# SCACHE_MMU_DSP register map
Vendor: Texas Instruments
Peripheral module from a debugger description file (folder omap5430_ES2_PUBLIC).
Registers are 32-bit, access per field, reset 0x0 unless marked. A register's access mark holds for its fields unless they carry their own. Offsets are as the file gives them; lines under a group give offsets from that group; [hi:lo] are bit positions; {n}, {i} and the like mark numbered series; 'fields as' and 'values as' point back to an identical list; <NAME> marks a mode.

## SCACHE_MMU_DSP
{0x0+4i} SCACHE_MMU_LARGE_ADDR_i_{i} (i=0..7)
  [31:25] ADDRESS rw — logical source address
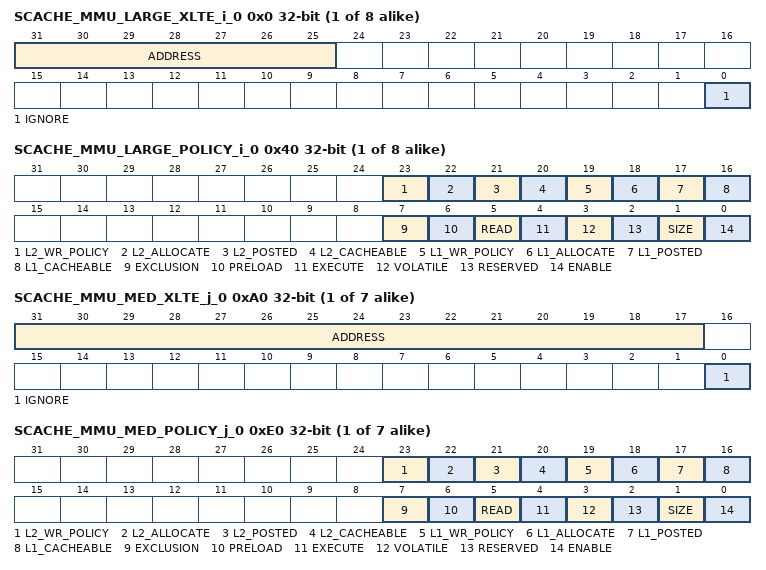
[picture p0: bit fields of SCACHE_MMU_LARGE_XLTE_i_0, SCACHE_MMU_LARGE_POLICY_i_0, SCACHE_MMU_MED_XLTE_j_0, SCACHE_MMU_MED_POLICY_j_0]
{0x0+4i} SCACHE_MMU_LARGE_XLTE_i_{i} (i=0..7) — Large page translated address
  [31:25] ADDRESS rw — Logical source translated address
  [0] IGNORE rw — Do not use translated address.
{0x40+4i} SCACHE_MMU_LARGE_POLICY_i_{i} (i=0..7)
  [23] L2_WR_POLICY rw — L2 write policy
    0=write_through; 1=write_back
  [22] L2_ALLOCATE rw — L2 allocate policy
    0=no_writes_are_allocated; 1=follow_sideband
  [21] L2_POSTED rw — L2 posted policy
    0=not_posted; 1=posted
  [20] L2_CACHEABLE rw — L2 cache policy
    0=non-cacheable; 1=cacheable
  [19] L1_WR_POLICY rw — L1 write policy
    0=write_through; 1=write_back
  [18] L1_ALLOCATE rw — L1 allocate policy
    0=no_writes_are_allocated; 1=follow_sideband
  [17] L1_POSTED rw — L1 posted policy
    0=not_posted; 1=posted
  [16] L1_CACHEABLE rw — L1 cache policy
    0=non-cacheable; 1=cacheable
  [7] EXCLUSION rw — cache exclusion
    0=do_not_send_exclusion_sideband; 1=send_exclusion_sideband
  [6] PRELOAD rw — preload region
    0=do_not_preload; 1=preload
  [5] READ rw — read only
  [4] EXECUTE rw — execute only
  [3] VOLATILE rw — volatile qualifier, see policy matrix
    0=do_not_follow_volatile_qualifier; 1=follow_volatile_qualifier
  [2] RESERVED rw — Read returns 0. Write has no effect.
  [1] SIZE rw — size of page
  [0] ENABLE rw — enable page
    0=page_not_enabled; 1=page_enabled
{0x60+4i} SCACHE_MMU_MED_ADDR_j_{i} (i=0..6)
  [31:17] ADDRESS rw — logical source address
{0xA0+4i} SCACHE_MMU_MED_XLTE_j_{i} (i=0..6) — Medium page translated address
  [31:17] ADDRESS rw — Logical source translated address
  [0] IGNORE rw — Do not use translated address.
{0xE0+4i} SCACHE_MMU_MED_POLICY_j_{i} (i=0..6)
  [23] L2_WR_POLICY rw — L2 write policy
    0=write_through; 1=write_back
  [22] L2_ALLOCATE rw — L2 allocate policy
    0=no_writes_are_allocated; 1=follow_sideband
  [21] L2_POSTED rw — L2 posted policy
    0=non_posted; 1=posted
  [20] L2_CACHEABLE rw — L2 cache policy
    0=non-cacheable; 1=cacheable
  [19] L1_WR_POLICY rw — L1 write policy
    0=write_through; 1=write_back
  [18] L1_ALLOCATE rw — L1 allocate policy
    0=no_writes_are_allocated; 1=follow_sideband
  [17] L1_POSTED rw — L1 posted policy
    0=non_posted; 1=posted
  [16] L1_CACHEABLE rw — L1 cache policy
    0=non-cacheable; 1=cacheable
  [7] EXCLUSION rw — cache exclusion
    0=do_not_send_exclusion_sideband; 1=send_exclusion_sideband
  [6] PRELOAD rw — preload region
    0=do_not_preload; 1=preload
  [5] READ rw — read only
  [4] EXECUTE rw — execute only
  [3] VOLATILE rw — volatile qualifier, see policy matrix
    values as SCACHE_MMU_LARGE_POLICY_i_0.VOLATILE
  [2] RESERVED rw — Read returns 0. Write has no effect.
  [1] SIZE rw — size of page
  [0] ENABLE rw — enable page
    0=page_not_enabled; 1=page_enabled
0x120 SCACHE_MMU_SMALL_ADDR_k_0 (reset mask 0xFFF) — Small Page0 Address
  [31:12] ADDRESS rw — logical source address
0x124 SCACHE_MMU_SMALL_ADDR_k_1 (reset mask 0xFFF) — Small Page0 Address
  [31:12] ADDRESS rw — logical source address
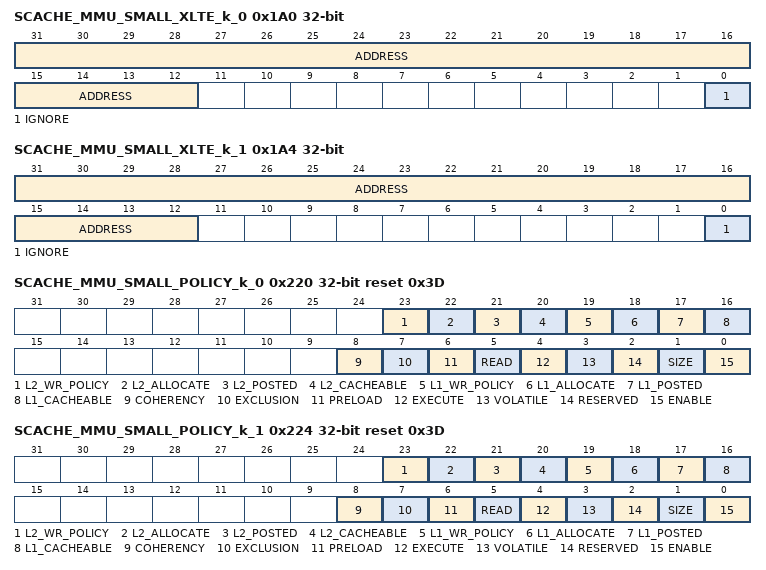
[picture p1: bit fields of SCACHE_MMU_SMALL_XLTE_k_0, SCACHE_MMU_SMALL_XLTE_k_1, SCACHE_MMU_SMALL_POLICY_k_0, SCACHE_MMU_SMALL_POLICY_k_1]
0x1A0 SCACHE_MMU_SMALL_XLTE_k_0 — Small page translated address
  [31:12] ADDRESS rw — Logical source translated address
  [0] IGNORE rw — Do not use translated address.
0x1A4 SCACHE_MMU_SMALL_XLTE_k_1 — Small page translated address
  fields as SCACHE_MMU_SMALL_XLTE_k_0
0x220 SCACHE_MMU_SMALL_POLICY_k_0 reset 0x3D — Small page0 policy
  [23] L2_WR_POLICY rw — L2 write policy
    0=write_through; 1=write_back
  [22] L2_ALLOCATE rw — L2 allocate policy
    0=no_writes_are_allocated; 1=follow_sideband
  [21] L2_POSTED rw — L2 posted policy
    0=non_posted; 1=posted
  [20] L2_CACHEABLE rw — L2 cache policy
    0=non-cacheable; 1=cacheable
  [19] L1_WR_POLICY rw — L1 write policy
    0=write_through; 1=write_back
  [18] L1_ALLOCATE rw — L1 allocate policy
    0=no_writes_are_allocated; 1=follow_sideband
  [17] L1_POSTED rw — L1 posted policy
    0=non_posted; 1=posted
  [16] L1_CACHEABLE rw — L1 cache policy
    0=non-cacheable; 1=cacheable
  [8] COHERENCY ro
  [7] EXCLUSION rw — cache exclusion
    0=do_not_send_exclusion_sideband; 1=send_exclusion_sideband
  [6] PRELOAD rw — preload region
    0=do_not_preload; 1=preload
  [5] READ rw — read only
  [4] EXECUTE rw — execute only
  [3] VOLATILE rw — volatile qualifier, see policy matrix
    values as SCACHE_MMU_LARGE_POLICY_i_0.VOLATILE
  [2] RESERVED rw — Read returns 1. Write has no effect.
  [1] SIZE rw — size of page
  [0] ENABLE rw — enable page
    0=page_not_enabled; 1=page_enabled
0x224 SCACHE_MMU_SMALL_POLICY_k_1 reset 0x3D — Small page0 policy
  fields as SCACHE_MMU_SMALL_POLICY_k_0
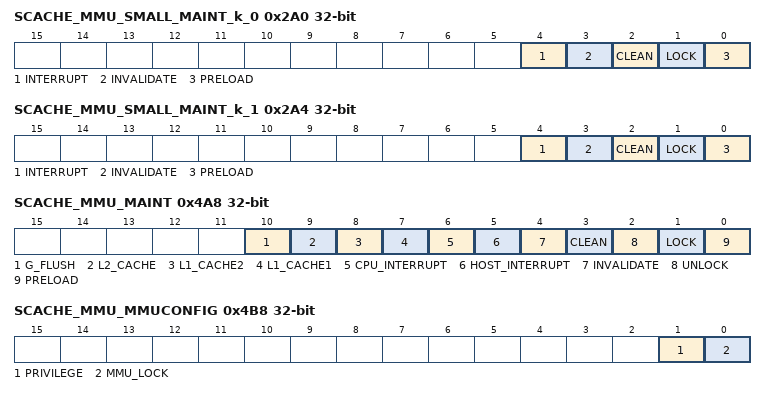
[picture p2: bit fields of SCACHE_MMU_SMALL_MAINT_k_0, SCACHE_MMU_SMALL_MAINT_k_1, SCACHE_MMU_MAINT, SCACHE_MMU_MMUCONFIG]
0x2A0 SCACHE_MMU_SMALL_MAINT_k_0
  [4] INTERRUPT rw — generate interrupt when maintenance operation is complete
  [3] INVALIDATE rw — invalidate page
  [2] CLEAN rw — evict page
  [1] LOCK rw — lock page
  [0] PRELOAD rw — preload page
0x2A4 SCACHE_MMU_SMALL_MAINT_k_1
  fields as SCACHE_MMU_SMALL_MAINT_k_0
0x4A8 SCACHE_MMU_MAINT — Maintenance Configuration Register
  [10] G_FLUSH rw — Global flush bit
    0=do_nothing,_global_flush_done; 1=invalidate_L1+L2
  [9] L2_CACHE rw — do maintenance operation in L2 Cache. Note: Hardware ensures that the maintenance operations are done in L1 first and then in L2
    0=do_nothing; 1=perform maintenance operation selected by the maintenance bits
  [8] L1_CACHE2 rw — do maintenance operation in L1 Cache 2
    values as L2_CACHE
  [7] L1_CACHE1 rw — do maintenance operation in L1 Cache1
    0=do_not_perform_maintenance_operation; 1=perform maintenance operation selected by the maintenance bits
  [6] CPU_INTERRUPT rw — generate interrupt to cpu when maintenance operation initiated by CPU is complete
    0=do_not_generate_interrupt; 1=generate_interrupt
  [5] HOST_INTERRUPT rw — generate interrupt when maintenance operation is complete
    0=do_not_generate_interrupt; 1=generate_interrupt
  [4] INVALIDATE rw — invalidate lines in region defined by maintenance start/end addresses
    0=do_nothing; 1=invalidate
  [3] CLEAN rw — evict dirty lines in region defined by maintenance start/end addresses
    0=do_nothing; 1=clean
  [2] UNLOCK rw — unlock region defined by maintenance start/end addresses
    0=do_nothing; 1=unlock
  [1] LOCK rw — lock region defined by maintenance start/end addresses
    0=do_nothing; 1=lock
  [0] PRELOAD rw — preload region defined by maintenance start/end addresses
    0=do_nothing; 1=preload
0x4AC SCACHE_MMU_MTSTART rw — Maintenance Start Configuratoin Register
  [31:0] BEGIN_ADDRESS — Start address of maintenance operations, resets to 0x0000 when finished
0x4B0 SCACHE_MMU_MTEND rw — Maintenance End Configuration Register
  [31:0] END_ADDRESS — End address of maintenance operations, resets to 0x0000 when finished
0x4B4 SCACHE_MMU_MAINTST ro — Maintenance Status Register
  [0] STATUS — status bit
    0=do_nothing,_maintenance_completed; 1=maintenance_ongoing
0x4B8 SCACHE_MMU_MMUCONFIG — MMU Configuration Register
  [1] PRIVILEGE rw — Privilege bit. Once this bit is set, only global flush, debugger, or hardware reset can clear.
    0=CPU_can_access_everything; 1=CPU_DMA_MMU_1 (CPU can only access maintenance, and DMA cannot access MMU at all.)
  [0] MMU_LOCK rw — MMU lock. Once this bit is set only a global flush, debugger, or hardware reset can clear.
    0=CPU_can_access_everything; 1=CPU_DMA_MMU._1 (CPU can only access maintenance, and DMA cannot access the MMU.)
